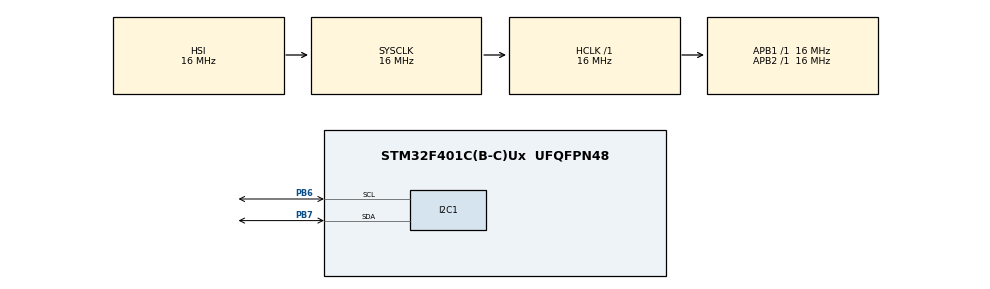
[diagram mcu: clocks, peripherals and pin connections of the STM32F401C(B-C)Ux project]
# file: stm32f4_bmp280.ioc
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Mcu.Family=STM32F4
Mcu.Name=STM32F401C(B-C)Ux
Mcu.Package=UFQFPN48
NVIC.PriorityGroup=NVIC_PRIORITYGROUP_4
PA13.Mode=Trace_Asynchronous_SW
PA13.Signal=SYS_JTMS-SWDIO
PA14.Mode=Trace_Asynchronous_SW
PA14.Signal=SYS_JTCK-SWCLK
PB3.Mode=Trace_Asynchronous_SW
PB3.Signal=SYS_JTDO-SWO
PB6.Mode=I2C
PB6.Signal=I2C1_SCL
PB7.Mode=I2C
PB7.Signal=I2C1_SDA
PH0\ -\ OSC_IN.Mode=HSE-External-Oscillator
PH0\ -\ OSC_IN.Signal=RCC_OSC_IN
PH1\ -\ OSC_OUT.Mode=HSE-External-Oscillator
PH1\ -\ OSC_OUT.Signal=RCC_OSC_OUT
ProjectManager.HeapSize=0x200
ProjectManager.StackSize=0x400
ProjectManager.TargetToolchain=STM32CubeIDE
RCC.AHBFreq_Value=16000000
RCC.APB1Freq_Value=16000000
RCC.APB2Freq_Value=16000000
RCC.CortexFreq_Value=16000000
RCC.HSE_VALUE=25000000
RCC.HSI_VALUE=16000000
RCC.LSE_VALUE=32768
RCC.SYSCLKFreq_VALUE=16000000
RCC.VCOOutputFreq_Value=192000000
board=custom

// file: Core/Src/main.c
/* USER CODE BEGIN Header */
/**
 ******************************************************************************
 * @file           : main.c
 * @brief          : Main program body
 ******************************************************************************
 * @attention
 *
 * Copyright (c) 2024 STMicroelectronics.
 * All rights reserved.
 *
 * This software is licensed under terms that can be found in the LICENSE file
 * in the root directory of this software component.
 * If no LICENSE file comes with this software, it is provided AS-IS.
 *
 ******************************************************************************
 */
/* USER CODE END Header */
#include "main.h"

/* USER CODE BEGIN Includes */
#include "bmp2.h"
#include "common.h"
#include <stdio.h>
/* USER CODE END Includes */

I2C_HandleTypeDef hi2c1;

/* USER CODE BEGIN PV */
struct bmp2_dev dev;
struct bmp2_config conf;
/* USER CODE END PV */

void SystemClock_Config(void);
static void MX_GPIO_Init(void);
static void MX_I2C1_Init(void);

/* USER CODE BEGIN PFP */
/*!
 *  @brief This internal API is used to get compensated pressure and temperature data.
 *
 *  @param[in] period   : Contains the delay in microseconds
 *  @param[in] dev      : Structure instance of bmp2_dev.
 *
 *  @return Status of execution.
 */
static int8_t get_data(uint32_t period, struct bmp2_dev *dev);
/* USER CODE END PFP */

int main(void)
{

    /* MCU Configuration--------------------------------------------------------*/

    /* Reset of all peripherals, Initializes the Flash interface and the Systick. */
    HAL_Init();

    /* Configure the system clock */
    SystemClock_Config();

    /* Initialize all configured peripherals */
    MX_GPIO_Init();
    MX_I2C1_Init();
    /* USER CODE BEGIN 2 */
    printf("Starting\r\n");

    int8_t rslt;
    uint32_t meas_time;

    dev.intf_ptr = &hi2c1;

    /* Interface selection is to be updated as parameter
     * For I2C :  BMP2_I2C_INTF
     * For SPI :  BMP2_SPI_INTF
     */
    rslt = bmp2_interface_selection(&dev, BMP2_I2C_INTF);
    bmp2_error_codes_print_result("bmp2_interface_selection", rslt);

    rslt = bmp2_init(&dev);
    bmp2_error_codes_print_result("bmp2_init", rslt);

    /* Always read the current settings before writing, especially when all the configuration is not modified */
    rslt = bmp2_get_config(&conf, &dev);
    bmp2_error_codes_print_result("bmp2_get_config", rslt);

    /* Configuring the over-sampling mode, filter coefficient and output data rate */
    /* Overwrite the desired settings */
    conf.filter = BMP2_FILTER_OFF;

    /* Over-sampling mode is set as high resolution i.e., os_pres = 8x and os_temp = 1x */
    conf.os_mode = BMP2_OS_MODE_HIGH_RESOLUTION;

    /* Setting the output data rate */
    conf.odr = BMP2_ODR_250_MS;

    rslt = bmp2_set_config(&conf, &dev);
    bmp2_error_codes_print_result("bmp2_set_config", rslt);

    /* Set normal power mode */
    rslt = bmp2_set_power_mode(BMP2_POWERMODE_NORMAL, &conf, &dev);
    bmp2_error_codes_print_result("bmp2_set_power_mode", rslt);

    /* Calculate measurement time in microseconds */
    rslt = bmp2_compute_meas_time(&meas_time, &conf, &dev);
    bmp2_error_codes_print_result("bmp2_compute_meas_time", rslt);

    /* Read pressure and temperature data */
    rslt = get_data(meas_time, &dev);
    bmp2_error_codes_print_result("get_data", rslt);

    // bmp2_coines_deinit();
    /* USER CODE END 2 */

    /* Infinite loop */
    while (1) {

        /* USER CODE BEGIN 3 */
        // printf("Hello\r\n");
        HAL_Delay(1000);
    }
    /* USER CODE END 3 */
}

void SystemClock_Config(void)
{
    RCC_OscInitTypeDef RCC_OscInitStruct =
        {0};
    RCC_ClkInitTypeDef RCC_ClkInitStruct =
        {0};

    /** Configure the main internal regulator output voltage
     */
    __HAL_RCC_PWR_CLK_ENABLE();
    __HAL_PWR_VOLTAGESCALING_CONFIG(PWR_REGULATOR_VOLTAGE_SCALE2);

    /** Initializes the RCC Oscillators according to the specified parameters
     * in the RCC_OscInitTypeDef structure.
     */
    RCC_OscInitStruct.OscillatorType = RCC_OSCILLATORTYPE_HSI;
    RCC_OscInitStruct.HSIState = RCC_HSI_ON;
    RCC_OscInitStruct.HSICalibrationValue = RCC_HSICALIBRATION_DEFAULT;
    RCC_OscInitStruct.PLL.PLLState = RCC_PLL_NONE;
    if (HAL_RCC_OscConfig(&RCC_OscInitStruct) != HAL_OK) {
        Error_Handler();
    }

    /** Initializes the CPU, AHB and APB buses clocks
     */
    RCC_ClkInitStruct.ClockType = RCC_CLOCKTYPE_HCLK | RCC_CLOCKTYPE_SYSCLK | RCC_CLOCKTYPE_PCLK1 | RCC_CLOCKTYPE_PCLK2;
    RCC_ClkInitStruct.SYSCLKSource = RCC_SYSCLKSOURCE_HSI;
    RCC_ClkInitStruct.AHBCLKDivider = RCC_SYSCLK_DIV1;
    RCC_ClkInitStruct.APB1CLKDivider = RCC_HCLK_DIV1;
    RCC_ClkInitStruct.APB2CLKDivider = RCC_HCLK_DIV1;

    if (HAL_RCC_ClockConfig(&RCC_ClkInitStruct, FLASH_LATENCY_0) != HAL_OK) {
        Error_Handler();
    }
}

static void MX_I2C1_Init(void)
{

    hi2c1.Instance = I2C1;
    hi2c1.Init.ClockSpeed = 100000;
    hi2c1.Init.DutyCycle = I2C_DUTYCYCLE_2;
    hi2c1.Init.OwnAddress1 = 0;
    hi2c1.Init.AddressingMode = I2C_ADDRESSINGMODE_7BIT;
    hi2c1.Init.DualAddressMode = I2C_DUALADDRESS_DISABLE;
    hi2c1.Init.OwnAddress2 = 0;
    hi2c1.Init.GeneralCallMode = I2C_GENERALCALL_DISABLE;
    hi2c1.Init.NoStretchMode = I2C_NOSTRETCH_DISABLE;
    if (HAL_I2C_Init(&hi2c1) != HAL_OK) {
        Error_Handler();
    }
}

static void MX_GPIO_Init(void)
{

    /* GPIO Ports Clock Enable */
    __HAL_RCC_GPIOH_CLK_ENABLE();
    __HAL_RCC_GPIOA_CLK_ENABLE();
    __HAL_RCC_GPIOB_CLK_ENABLE();

}

/* USER CODE BEGIN 4 */
/*!
 *  @brief This internal API is used to get compensated pressure and temperature data.
 */
static int8_t get_data(uint32_t period, struct bmp2_dev *dev)
{
    int8_t rslt = BMP2_E_NULL_PTR;
    int8_t idx = 1;
    struct bmp2_status status;
    struct bmp2_data comp_data;

    printf("Measurement delay : %lu us\n", (long unsigned int)period);

    while (idx <= 50) {
        rslt = bmp2_get_status(&status, dev);
        bmp2_error_codes_print_result("bmp2_get_status", rslt);

        if (status.measuring == BMP2_MEAS_DONE) {
            /* Delay between measurements */
            dev->delay_us(period, dev->intf_ptr);

            /* Read compensated data */
            rslt = bmp2_get_sensor_data(&comp_data, dev);
            bmp2_error_codes_print_result("bmp2_get_sensor_data", rslt);

#ifdef BMP2_64BIT_COMPENSATION
            comp_data.pressure = comp_data.pressure / 256;
#endif

#ifdef BMP2_DOUBLE_COMPENSATION
            printf("Data[%d]:    Temperature: %.4lf deg C   Pressure: %.4lf Pa\n",
                   idx, comp_data.temperature, comp_data.pressure);
#else
            printf("Data[%d]:    Temperature: %ld deg C Pressure: %lu Pa\n", idx, (long int)comp_data.temperature,
                   (long unsigned int)comp_data.pressure);
#endif

            idx++;
        }
    }

    return rslt;
}
/* USER CODE END 4 */

void Error_Handler(void)
{
    __disable_irq();
    while (1) {
    }
}
